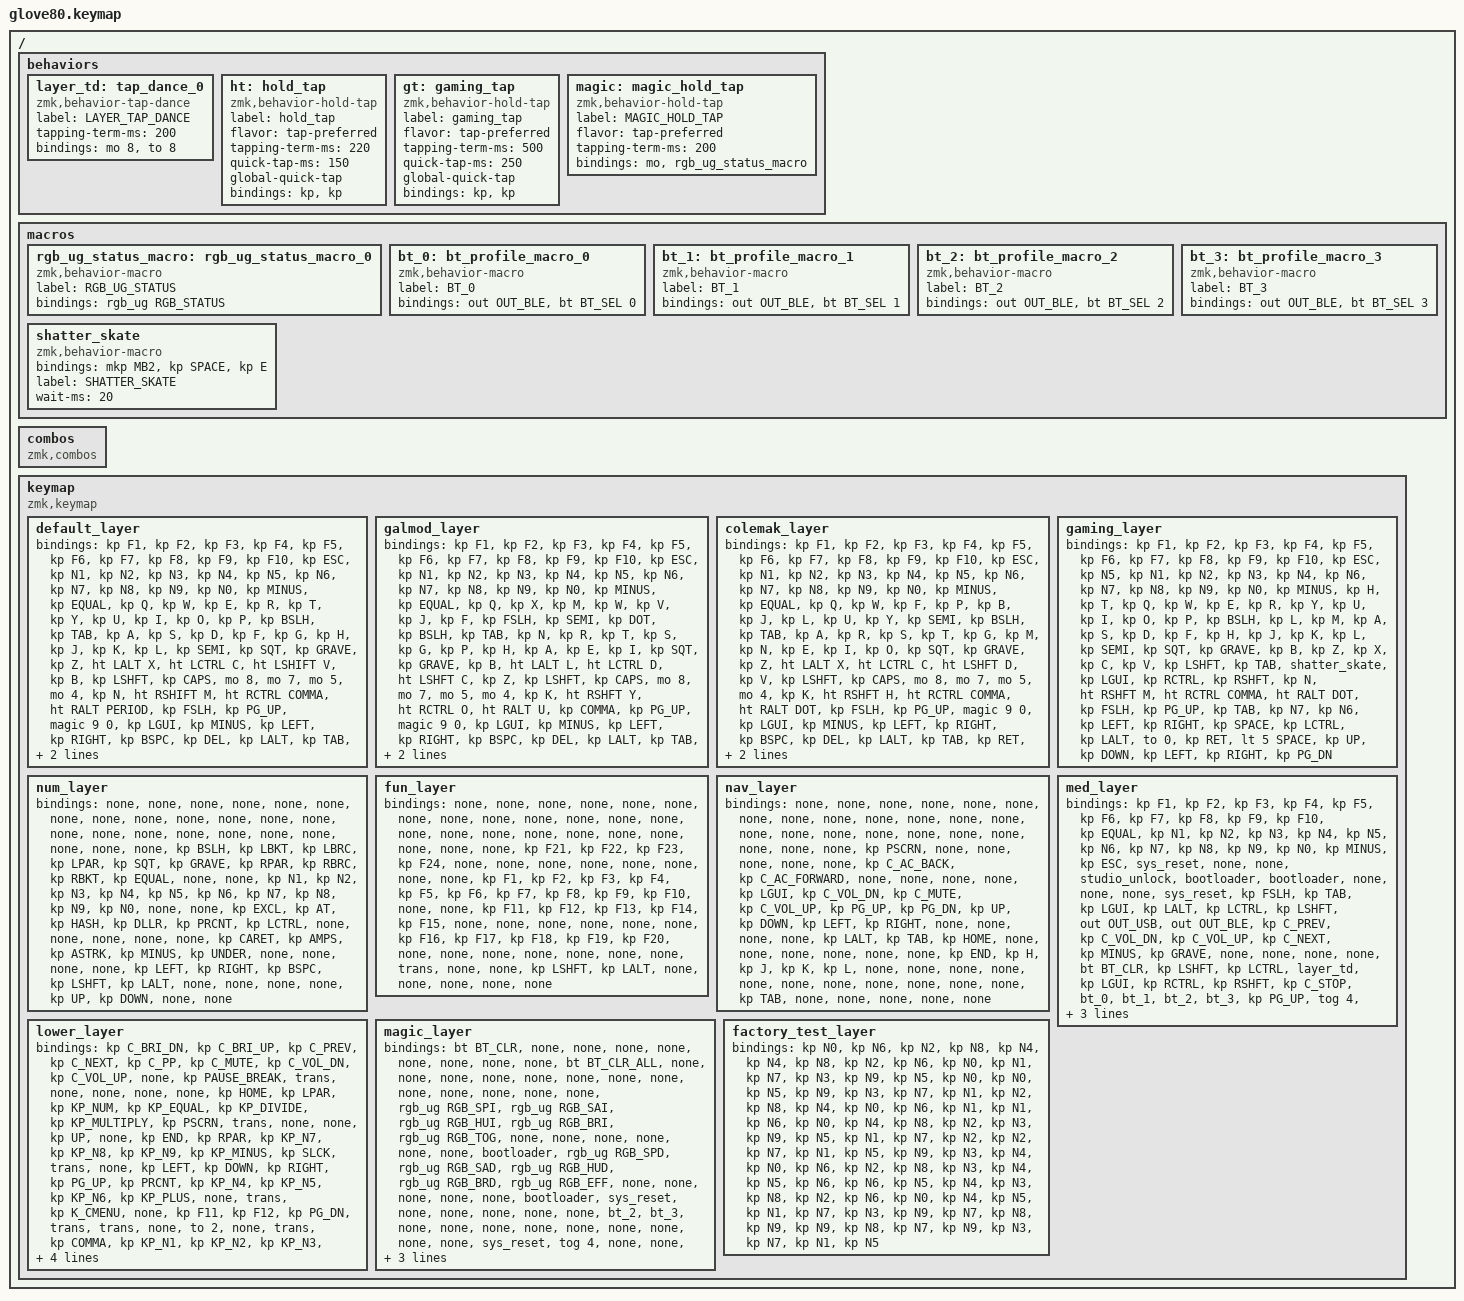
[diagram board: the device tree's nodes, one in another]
/*
 * Copyright (c) 2020 The ZMK Contributors
 *
 * SPDX-License-Identifier: MIT
 */

#include <behaviors.dtsi>
#include <dt-bindings/zmk/bt.h>
#include <dt-bindings/zmk/keys.h>
#include <dt-bindings/zmk/outputs.h>
#include <dt-bindings/zmk/pointing.h>
#include <dt-bindings/zmk/rgb.h>

#define HYPER LC(LS(LG(LALT)))

// layers

#define DEFAULT 0
#define ALT     1
#define COL     2
#define GAMING  3
#define NUM     4
#define FUN     5
#define NAV     6
#define MED     7
#define LOWER   8
#define MAG     9

/ {
    behaviors {
        layer_td: tap_dance_0 {
            compatible = "zmk,behavior-tap-dance";
            label = "LAYER_TAP_DANCE";
            #binding-cells = <0>;
            tapping-term-ms = <200>;
            bindings = <&mo 8>, <&to 8>;
        };

        ht: hold_tap {
            label = "hold_tap";
            compatible = "zmk,behavior-hold-tap";
            #binding-cells = <2>;
            flavor = "tap-preferred";
            tapping-term-ms = <220>;
            quick-tap-ms = <150>;
            global-quick-tap;
            bindings = <&kp>, <&kp>;
        };

        gt: gaming_tap {
            label = "gaming_tap";
            compatible = "zmk,behavior-hold-tap";
            #binding-cells = <2>;
            flavor = "tap-preferred";
            tapping-term-ms = <500>;
            quick-tap-ms = <250>;
            global-quick-tap;
            bindings = <&kp>, <&kp>;
        };

        magic: magic_hold_tap {
            compatible = "zmk,behavior-hold-tap";
            label = "MAGIC_HOLD_TAP";
            #binding-cells = <2>;
            flavor = "tap-preferred";
            tapping-term-ms = <200>;
            bindings = <&mo>, <&rgb_ug_status_macro>;
        };
    };

    macros {
        rgb_ug_status_macro: rgb_ug_status_macro_0 {
            label = "RGB_UG_STATUS";
            compatible = "zmk,behavior-macro";
            #binding-cells = <0>;
            bindings = <&rgb_ug RGB_STATUS>;
        };

        bt_0: bt_profile_macro_0 {
            label = "BT_0";
            compatible = "zmk,behavior-macro";
            #binding-cells = <0>;
            bindings = <&out OUT_BLE &bt BT_SEL 0>;
        };

        bt_1: bt_profile_macro_1 {
            label = "BT_1";
            compatible = "zmk,behavior-macro";
            #binding-cells = <0>;
            bindings = <&out OUT_BLE &bt BT_SEL 1>;
        };

        bt_2: bt_profile_macro_2 {
            label = "BT_2";
            compatible = "zmk,behavior-macro";
            #binding-cells = <0>;
            bindings = <&out OUT_BLE &bt BT_SEL 2>;
        };

        bt_3: bt_profile_macro_3 {
            label = "BT_3";
            compatible = "zmk,behavior-macro";
            #binding-cells = <0>;
            bindings = <&out OUT_BLE &bt BT_SEL 3>;
        };

        shatter_skate: shatter_skate {
            compatible = "zmk,behavior-macro";
            #binding-cells = <0>;
            bindings = <&mkp MB2 &kp SPACE &kp E>;
            label = "SHATTER_SKATE";
            wait-ms = <20>;
        };
    };

    combos { compatible = "zmk,combos"; };

    keymap {
        compatible = "zmk,keymap";

        default_layer {
            bindings = <
&kp F1      &kp F2    &kp F3      &kp F4       &kp F5                                                                                    &kp F6        &kp F7           &kp F8           &kp F9    &kp F10
&kp ESC     &kp N1    &kp N2      &kp N3       &kp N4        &kp N5                                                              &kp N6  &kp N7        &kp N8           &kp N9           &kp N0    &kp MINUS
&kp EQUAL   &kp Q     &kp W       &kp E        &kp R         &kp T                                                               &kp Y   &kp U         &kp I            &kp O            &kp P     &kp BSLH
&kp TAB     &kp A     &kp S       &kp D        &kp F         &kp G                                                               &kp H   &kp J         &kp K            &kp L            &kp SEMI  &kp SQT
&kp GRAVE   &kp Z     &ht LALT X  &ht LCTRL C  &ht LSHIFT V  &kp B   &kp LSHFT  &kp CAPS  &mo 8     &mo 7    &mo 5    &mo 4      &kp N   &ht RSHIFT M  &ht RCTRL COMMA  &ht RALT PERIOD  &kp FSLH  &kp PG_UP
&magic 9 0  &kp LGUI  &kp MINUS   &kp LEFT     &kp RIGHT             &kp BSPC   &kp DEL   &kp LALT  &kp TAB  &kp RET  &kp SPACE          &kp UP        &kp DOWN         &kp HOME         &kp END   &kp PG_DN
            >;
        };

        galmod_layer {
            // ---------------------------------------------------------------------------------------------------------------------------------
            // |  F1   |  F2 |  F3 |  F4  |  F5  |                                                               |  F6   |  F7   |  F8  |   F9  |  F10 |
            // |  =    |  1  |  2  |  3   |  4   |  5   |                                                 |  6   |   7   |   8   |  9   |   0   |   -  |
            // |  TAB  |  Q  |  W  |  F   |  P   |  B   |                                                 |  J   |   L   |   U   |  Y   |   ;   |   \  |
            // |  ESC  |  A  |  R  |  S   |  T   |  G   |                                                 |  M   |   N   |   E   |  I   |   O   |   '  |
            // |   `   |  Z  |  X  |  C   |  D   |  V   | LSHFT | LCTRL | LOWER | | LGUI  | RCTRL | RSHFT |  K   |   H   |   ,   |  .   |   /   | PGUP |
            // | MAGIC | HOME| END | LEFT | RIGHT|      | BSPC  | DEL   | LALT  | | RALT  | RET   | SPACE |      |  UP   | DOWN  |  [   |   ]   | PGDN |

            bindings = <
&kp F1      &kp F2    &kp F3      &kp F4       &kp F5                                                                                   &kp F6       &kp F7       &kp F8      &kp F9     &kp F10
&kp ESC     &kp N1    &kp N2      &kp N3       &kp N4       &kp N5                                                              &kp N6  &kp N7       &kp N8       &kp N9      &kp N0     &kp MINUS
&kp EQUAL   &kp Q     &kp X       &kp M        &kp W        &kp V                                                               &kp J   &kp F        &kp FSLH     &kp SEMI    &kp DOT    &kp BSLH
&kp TAB     &kp N     &kp R       &kp T        &kp S        &kp G                                                               &kp P   &kp H        &kp A        &kp E       &kp I      &kp SQT
&kp GRAVE   &kp B     &ht LALT L  &ht LCTRL D  &ht LSHFT C  &kp Z   &kp LSHFT  &kp CAPS  &mo 8     &mo 7    &mo 5    &mo 4      &kp K   &ht RSHFT Y  &ht RCTRL O  &ht RALT U  &kp COMMA  &kp PG_UP
&magic 9 0  &kp LGUI  &kp MINUS   &kp LEFT     &kp RIGHT            &kp BSPC   &kp DEL   &kp LALT  &kp TAB  &kp RET  &kp SPACE          &kp UP       &kp DOWN     &kp HOME    &kp END    &kp PG_DN
            >;
        };

        colemak_layer {
            bindings = <
&kp F1      &kp F2    &kp F3      &kp F4       &kp F5                                                                                   &kp F6       &kp F7           &kp F8        &kp F9    &kp F10
&kp ESC     &kp N1    &kp N2      &kp N3       &kp N4       &kp N5                                                              &kp N6  &kp N7       &kp N8           &kp N9        &kp N0    &kp MINUS
&kp EQUAL   &kp Q     &kp W       &kp F        &kp P        &kp B                                                               &kp J   &kp L        &kp U            &kp Y         &kp SEMI  &kp BSLH
&kp TAB     &kp A     &kp R       &kp S        &kp T        &kp G                                                               &kp M   &kp N        &kp E            &kp I         &kp O     &kp SQT
&kp GRAVE   &kp Z     &ht LALT X  &ht LCTRL C  &ht LSHFT D  &kp V   &kp LSHFT  &kp CAPS  &mo 8     &mo 7    &mo 5    &mo 4      &kp K   &ht RSHFT H  &ht RCTRL COMMA  &ht RALT DOT  &kp FSLH  &kp PG_UP
&magic 9 0  &kp LGUI  &kp MINUS   &kp LEFT     &kp RIGHT            &kp BSPC   &kp DEL   &kp LALT  &kp TAB  &kp RET  &kp SPACE          &kp UP       &kp DOWN         &kp HOME      &kp END   &kp PG_DN
            >;
        };

        gaming_layer {
            bindings = <
&kp F1     &kp F2  &kp F3  &kp F4    &kp F5                                                                                             &kp F6       &kp F7           &kp F8        &kp F9     &kp F10
&kp ESC    &kp N5  &kp N1  &kp N2    &kp N3     &kp N4                                                                          &kp N6  &kp N7       &kp N8           &kp N9        &kp N0     &kp MINUS
&kp H      &kp T   &kp Q   &kp W     &kp E      &kp R                                                                           &kp Y   &kp U        &kp I            &kp O         &kp P      &kp BSLH
&kp L      &kp M   &kp A   &kp S     &kp D      &kp F                                                                           &kp H   &kp J        &kp K            &kp L         &kp SEMI   &kp SQT
&kp GRAVE  &kp B   &kp Z   &kp X     &kp C      &kp V   &kp LSHFT  &kp TAB    &shatter_skate  &kp LGUI  &kp RCTRL  &kp RSHFT    &kp N   &ht RSHFT M  &ht RCTRL COMMA  &ht RALT DOT  &kp FSLH   &kp PG_UP
&kp TAB    &kp N7  &kp N6  &kp LEFT  &kp RIGHT          &kp SPACE  &kp LCTRL  &kp LALT        &to 0     &kp RET    &lt 5 SPACE          &kp UP       &kp DOWN         &kp LEFT      &kp RIGHT  &kp PG_DN
            >;
        };

        num_layer {
            bindings = <
&none  &none     &none     &none     &none                                                                                 &none     &none      &none      &none      &none
&none  &none     &none     &none     &none      &none                                                           &none      &none     &none      &none      &none      &none
&none  &kp BSLH  &kp LBKT  &kp LBRC  &kp LPAR   &kp SQT                                                         &kp GRAVE  &kp RPAR  &kp RBRC   &kp RBKT   &kp EQUAL  &none
&none  &kp N1    &kp N2    &kp N3    &kp N4     &kp N5                                                          &kp N6     &kp N7    &kp N8     &kp N9     &kp N0     &none
&none  &kp EXCL  &kp AT    &kp HASH  &kp DLLR   &kp PRCNT  &kp LCTRL  &none      &none     &none  &none  &none  &kp CARET  &kp AMPS  &kp ASTRK  &kp MINUS  &kp UNDER  &none
&none  &none     &none     &kp LEFT  &kp RIGHT             &kp BSPC   &kp LSHFT  &kp LALT  &none  &none  &none             &none     &kp UP     &kp DOWN   &none      &none
            >;
        };

        fun_layer {
            bindings = <
&none  &none    &none    &none    &none                                                                        &none    &none    &none    &none    &none
&none  &none    &none    &none    &none    &none                                                      &none    &none    &none    &none    &none    &none
&none  &kp F21  &kp F22  &kp F23  &kp F24  &none                                                      &none    &none    &none    &none    &none    &none
&none  &kp F1   &kp F2   &kp F3   &kp F4   &kp F5                                                     &kp F6   &kp F7   &kp F8   &kp F9   &kp F10  &none
&none  &kp F11  &kp F12  &kp F13  &kp F14  &kp F15  &none  &none   &none  &none  &none      &none     &kp F16  &kp F17  &kp F18  &kp F19  &kp F20  &none
&none  &none    &none    &none    &none             &none  &trans  &none  &none  &kp LSHFT  &kp LALT           &none    &none    &none    &none    &none
            >;
        };

        nav_layer {
            bindings = <
&none  &none      &none         &none       &none                                                                           &none          &none             &none     &none      &none
&none  &none      &none         &none       &none         &none                                                  &none      &none          &none             &none     &none      &none
&none  &kp PSCRN  &none         &none       &none         &none                                                  &none      &kp C_AC_BACK  &kp C_AC_FORWARD  &none     &none      &none
&none  &kp LGUI   &kp C_VOL_DN  &kp C_MUTE  &kp C_VOL_UP  &kp PG_UP                                              &kp PG_DN  &kp UP         &kp DOWN          &kp LEFT  &kp RIGHT  &none
&none  &none      &none         &kp LALT    &kp TAB       &kp HOME   &none  &none  &none  &none  &none  &none    &kp END    &kp H          &kp J             &kp K     &kp L      &none
&none  &none      &none         &none       &none                    &none  &none  &none  &none  &none  &kp TAB             &none          &none             &none     &none      &none
            >;
        };

        med_layer {
            bindings = <
&kp F1     &kp F2      &kp F3    &kp F4     &kp F5                                                                                                       &kp F6      &kp F7        &kp F8        &kp F9      &kp F10
&kp EQUAL  &kp N1      &kp N2    &kp N3     &kp N4          &kp N5                                                                         &kp N6        &kp N7      &kp N8        &kp N9        &kp N0      &kp MINUS
&kp ESC    &sys_reset  &none     &none      &studio_unlock  &bootloader                                                                    &bootloader   &none       &none         &none         &sys_reset  &kp FSLH
&kp TAB    &kp LGUI    &kp LALT  &kp LCTRL  &kp LSHFT       &out OUT_USB                                                                   &out OUT_BLE  &kp C_PREV  &kp C_VOL_DN  &kp C_VOL_UP  &kp C_NEXT  &kp MINUS
&kp GRAVE  &none       &none     &none      &none           &bt BT_CLR    &kp LSHFT  &kp LCTRL  &layer_td  &kp LGUI  &kp RCTRL  &kp RSHFT  &kp C_STOP    &bt_0       &bt_1         &bt_2         &bt_3       &kp PG_UP
&tog 4     &kp HOME    &kp END   &kp LEFT   &kp RIGHT                     &trans     &kp DEL    &kp LALT   &kp RALT  &kp RET    &kp SPACE                &kp UP      &kp DOWN      &kp LBKT      &kp RBKT    &kp PG_DN
            >;
        };

        lower_layer {
            bindings = <
&kp C_BRI_DN  &kp C_BRI_UP  &kp C_PREV  &kp C_NEXT  &kp C_PP                                                                       &kp C_MUTE  &kp C_VOL_DN  &kp C_VOL_UP   &none            &kp PAUSE_BREAK
&trans        &none         &none       &none       &none      &kp HOME                                                 &kp LPAR   &kp KP_NUM  &kp KP_EQUAL  &kp KP_DIVIDE  &kp KP_MULTIPLY  &kp PSCRN
&trans        &none         &none       &kp UP      &none      &kp END                                                  &kp RPAR   &kp KP_N7   &kp KP_N8     &kp KP_N9      &kp KP_MINUS     &kp SLCK
&trans        &none         &kp LEFT    &kp DOWN    &kp RIGHT  &kp PG_UP                                                &kp PRCNT  &kp KP_N4   &kp KP_N5     &kp KP_N6      &kp KP_PLUS      &none
&trans        &kp K_CMENU   &none       &kp F11     &kp F12    &kp PG_DN  &trans  &trans  &none  &to 2  &none   &trans  &kp COMMA  &kp KP_N1   &kp KP_N2     &kp KP_N3      &kp KP_ENTER     &trans
&trans        &kp CAPS      &kp INS     &kp F11     &kp F12               &trans  &trans  &to 3  &to 1  &trans  &trans             &kp KP_N0   &kp KP_N0     &kp KP_DOT     &kp KP_ENTER     &trans
            >;
        };

        magic_layer {
            bindings = <
&bt BT_CLR   &none            &none            &none            &none                                                                                            &none  &none  &none  &none  &bt BT_CLR_ALL
&none        &none            &none            &none            &none            &none                                                                    &none  &none  &none  &none  &none  &none
&none        &rgb_ug RGB_SPI  &rgb_ug RGB_SAI  &rgb_ug RGB_HUI  &rgb_ug RGB_BRI  &rgb_ug RGB_TOG                                                          &none  &none  &none  &none  &none  &none
&bootloader  &rgb_ug RGB_SPD  &rgb_ug RGB_SAD  &rgb_ug RGB_HUD  &rgb_ug RGB_BRD  &rgb_ug RGB_EFF                                                          &none  &none  &none  &none  &none  &bootloader
&sys_reset   &none            &none            &none            &none            &none            &bt_2  &bt_3  &none         &none         &none  &none  &none  &none  &none  &none  &none  &sys_reset
&tog 4       &none            &none            &none            &none                             &bt_0  &bt_1  &out OUT_USB  &out OUT_BLE  &none  &none         &none  &none  &none  &none  &none
            >;
        };

        factory_test_layer {
            bindings = <
&kp N0  &kp N6  &kp N2  &kp N8  &kp N4                                                                  &kp N4  &kp N8  &kp N2  &kp N6  &kp N0
&kp N1  &kp N7  &kp N3  &kp N9  &kp N5  &kp N0                                                  &kp N0  &kp N5  &kp N9  &kp N3  &kp N7  &kp N1
&kp N2  &kp N8  &kp N4  &kp N0  &kp N6  &kp N1                                                  &kp N1  &kp N6  &kp N0  &kp N4  &kp N8  &kp N2
&kp N3  &kp N9  &kp N5  &kp N1  &kp N7  &kp N2                                                  &kp N2  &kp N7  &kp N1  &kp N5  &kp N9  &kp N3
&kp N4  &kp N0  &kp N6  &kp N2  &kp N8  &kp N3  &kp N4  &kp N5  &kp N6  &kp N6  &kp N5  &kp N4  &kp N3  &kp N8  &kp N2  &kp N6  &kp N0  &kp N4
&kp N5  &kp N1  &kp N7  &kp N3  &kp N9          &kp N7  &kp N8  &kp N9  &kp N9  &kp N8  &kp N7          &kp N9  &kp N3  &kp N7  &kp N1  &kp N5
            >;
        };
    };
};

/*
*/
